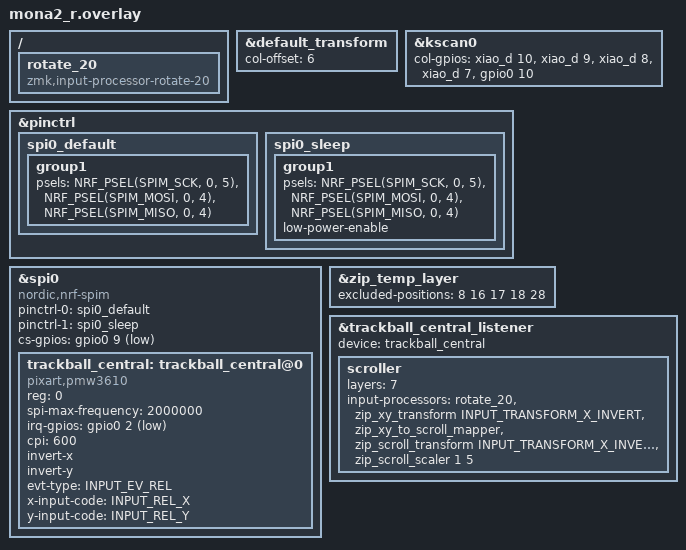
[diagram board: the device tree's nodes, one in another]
#include "mona2.dtsi"
#include <input/processors.dtsi>
#include <zephyr/dt-bindings/input/input-event-codes.h>

/ {
    rotate_20: rotate_20 {
        compatible = "zmk,input-processor-rotate-20";
        #input-processor-cells = <0>;
    };
};

&default_transform {
    col-offset = <6>;
};

&kscan0 {
        col-gpios
            = <&xiao_d 10 GPIO_ACTIVE_HIGH>
            , <&xiao_d 9 GPIO_ACTIVE_HIGH> 
            , <&xiao_d 8 GPIO_ACTIVE_HIGH> 
            , <&xiao_d 7 GPIO_ACTIVE_HIGH> 
            , <&gpio0 10 GPIO_ACTIVE_HIGH>
            ;
};

&pinctrl {
    spi0_default: spi0_default {
        group1 {
            psels = <NRF_PSEL(SPIM_SCK, 0, 5)>,
                <NRF_PSEL(SPIM_MOSI, 0, 4)>,
                <NRF_PSEL(SPIM_MISO, 0, 4)>;
        };
    };

    spi0_sleep: spi0_sleep {
        group1 {
            psels = <NRF_PSEL(SPIM_SCK, 0, 5)>,
                <NRF_PSEL(SPIM_MOSI, 0, 4)>,
                <NRF_PSEL(SPIM_MISO, 0, 4)>;
            low-power-enable;
        };
    };
};

&spi0 {
    status = "okay";
    compatible = "nordic,nrf-spim";
    pinctrl-0 = <&spi0_default>;
    pinctrl-1 = <&spi0_sleep>;
    pinctrl-names = "default", "sleep";
    cs-gpios = <&gpio0 9 GPIO_ACTIVE_LOW>;

    trackball_central: trackball_central@0 {
        status = "okay";
        compatible = "pixart,pmw3610";
        reg = <0>;
        spi-max-frequency = <2000000>;
        irq-gpios = <&gpio0 2 (GPIO_ACTIVE_LOW | GPIO_PULL_UP)>;
        cpi = <600>;
        //swap-xy;
        invert-x;
        invert-y;
        evt-type = <INPUT_EV_REL>;
        x-input-code = <INPUT_REL_X>;
        y-input-code = <INPUT_REL_Y>;
    };
};

&zip_temp_layer {
    excluded-positions = <
        8  // I
        16 // H
        17 // J
        18 // K
        28 // N
    >;
};


// Overrides for the input listener node
&trackball_central_listener {
    status = "okay";
    device = <&trackball_central>;

    scroller {
        layers = <7>;
        input-processors = 
            <&rotate_20>,                                        //20度回転
            <&zip_xy_transform INPUT_TRANSFORM_X_INVERT>,       //X軸反転
            <&zip_xy_to_scroll_mapper>,
            <&zip_scroll_transform INPUT_TRANSFORM_X_INVERT>,
            <&zip_scroll_scaler 1 5>;
    };
};
